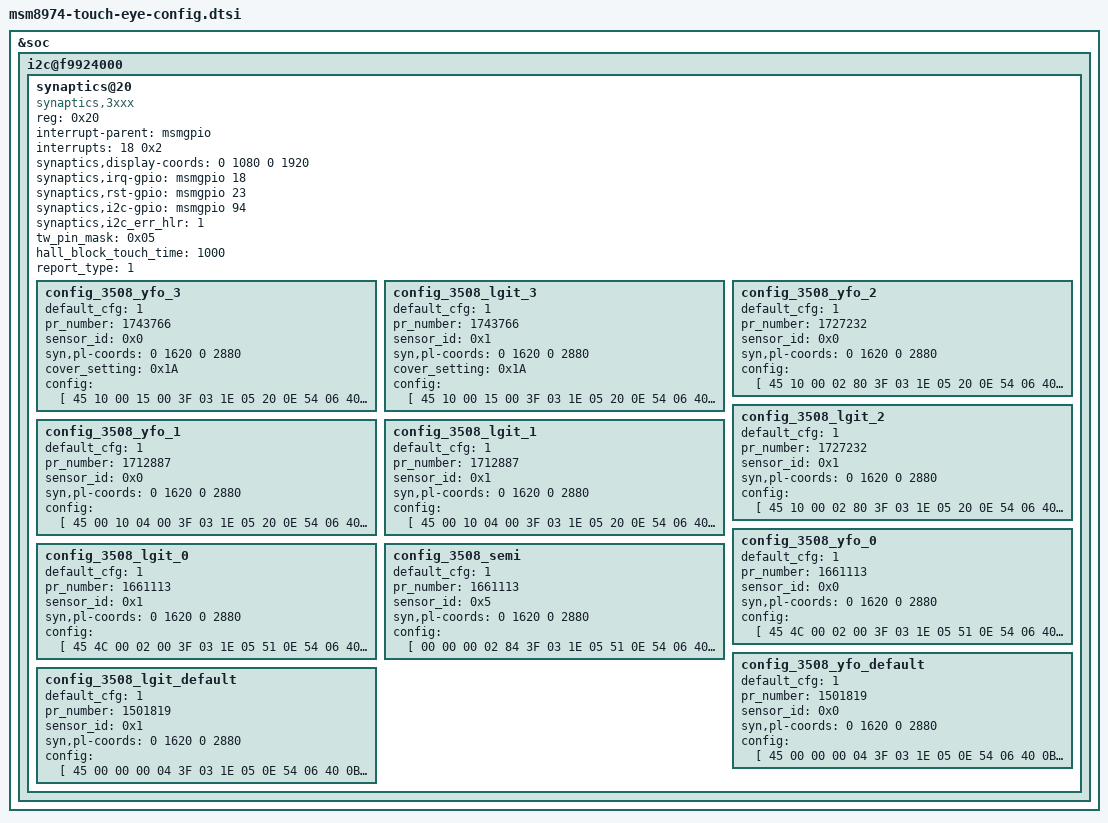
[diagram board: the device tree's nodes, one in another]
/* Copyright (c) 2013, The Linux Foundation. All rights reserved.
 *
 * This program is free software; you can redistribute it and/or modify
 * it under the terms of the GNU General Public License version 2 and
 * only version 2 as published by the Free Software Foundation.
 *
 * This program is distributed in the hope that it will be useful,
 * but WITHOUT ANY WARRANTY; without even the implied warranty of
 * MERCHANTABILITY or FITNESS FOR A PARTICULAR PURPOSE.  See the
 * GNU General Public License for more details.
 */

&soc {
	i2c@f9924000 {
		synaptics@20 {
			compatible               = "synaptics,3xxx";
			reg                      = <0x20>;
			interrupt-parent         = <&msmgpio>;
			interrupts               = <18 0x2>;
			synaptics,display-coords = <0 1080 0 1920>;
			synaptics,irq-gpio       = <&msmgpio 18 0x00>;
			synaptics,rst-gpio       = <&msmgpio 23 0x00>;
			synaptics,i2c-gpio       = <&msmgpio 94 0x00>;
			synaptics,i2c_err_hlr    = <1>;
			tw_pin_mask              = <0x05>;
			hall_block_touch_time    = <1000>;
			report_type              = <1>;

			config_3508_yfo_3 {
				default_cfg   = <1>;
				pr_number     = <1743766>;
				sensor_id     = <0x0>;
				syn,pl-coords = <0 1620 0 2880>;
				cover_setting = <0x1A>;
				config = [
					45 10 00 15 00 3F 03 1E
					05 20 0E 54 06 40 0B 6D
					41 F0 41 00 00 00 00 10
					1C 01 1E 05 EE 0A AC 01
					2D 0B 03 0C 03 55 C5 64
					CA 25 0D 05 8C 00 13 14
					80 0F 0A 78 00 01 01 07
					04 04 1E 40 19 C8 26 26
					80 80 00 00 C8 C0 53 5B
					80 26 19 01 40 40 32 50
					00 00 00 00 4C 04 6C 07
					3C 32 00 00 00 00 4C 04
					6C 07 1E 05 1E 04 0A 04
					0A 00 0A 04 04 01 01 00
					01 05 0A 00 10 00 32 00
					96 00 00 00 14 03 0C 0F
					0A 00 4B 00 FF FF FF FF
					FF FF FF FF FF FF FF FF
					FF FF FF FF FF FF FF FF
					FF FF FF FF FF FF FF FF
					FF FF FF FF FF 00 04 01
					80 0D 1B 00 00 FF F4 01
					FF FF BF 64 C8 00 00 C0
					80 00 10 0A 18 00 79 01
					FA 00 00 58 02 50 00 03
					03 07 07 03 C8 00 01 04
					04 3E 00 18 00 00 00 02
					00 01 29 04 3D 00 17 00
					01 00 02 00 01 2B 84 3B
					00 17 00 02 00 02 00 01
					2C 84 3A 00 17 00 03 00
					02 00 01 2D 04 39 00 16
					00 04 00 05 00 02 26 04
					38 00 16 00 05 00 05 00
					02 27 04 36 00 15 00 08
					00 05 00 02 29 04 35 00
					15 00 09 00 05 00 02 29
					02 03 03 03 03 03 03 03
					03 03 03 03 03 03 03 03
					00 00 00 00 00 00 1D 00
					06 00 A6 00 14 64 00 00
					1B 02 06 FF 14 A0 00 A0
					00 50 32 1E 03 0C 0C 14
					28 04 00 00 00 00 00 00
					00 00 00 00 17 B2 07 01
					03 01 01 01 01 01 03 04
					00 03 01 0B 0B 02 02 03
					04 04 28 00 06 04 00 3E
					2D 00 05 05 00 2A 02 00
					01 00 FA 28 00 2C 01 32
					00 01 FF FF FF FF FF FF
					FF FF FF FF FF FF FF FF
					FF FF FF FF FF FF FF FF
					00 01 00 00 FF FF FF FF
					FF FF FF FF FF FF FF FF
					FF FF FF FF 28 00 2C 01
					19 00 00 00 00 FF FF FF
					FF FF FF FF FF 51 51 51
					51 CD 0D 04 83 10 10 10
					10 61 24 05 11 12 13 14
					15 16 17 18 19 1A 1B 1C
					1D 1E 1F 20 FF FF FF FF
					FF FF 00 01 02 03 04 05
					06 07 08 09 0A 0B 0C 0D
					34 33 32 31 30 2F 2E 2D
					2C 2B 2A 29 28 27 FF FF
					FF FF 00 10 00 10 00 10
					00 10 80 80 80 80 80 80
					80 80 80 80 80 80 80 80
					80 80 80 80 80 80 80 80
					80 80 80 80 80 80 80 80
					80 80 80 80 80 80 80 80
					80 80 80 80 80 80 80 80
					80 80 80 80 80 80 80 80
					00 10 00 10 00 10 00 10
					00 00 23 FF FF FF 0E FF
					FF FF
				];
			};

			config_3508_lgit_3 {
				default_cfg   = <1>;
				pr_number     = <1743766>;
				sensor_id     = <0x1>;
				syn,pl-coords = <0 1620 0 2880>;
				cover_setting = <0x1A>;
				config = [
					45 10 00 15 00 3F 03 1E
					05 20 0E 54 06 40 0B 6D
					41 F0 41 00 00 00 00 10
					1C 01 1E 05 EE 0A AC 01
					2D 0B 03 0C 03 55 C5 64
					CA 25 0D 05 8C 00 13 14
					80 0F 0A 78 00 01 01 07
					04 04 1E 40 19 C8 26 26
					80 80 00 00 C8 C0 53 5B
					80 26 19 01 40 40 32 50
					00 00 00 00 4C 04 6C 07
					3C 32 00 00 00 00 4C 04
					6C 07 1E 05 1E 04 0A 04
					0A 00 0A 04 04 01 01 00
					01 05 0A 00 10 00 32 00
					96 00 00 00 14 03 0C 0F
					0A 00 4B 00 FF FF FF FF
					FF FF FF FF FF FF FF FF
					FF FF FF FF FF FF FF FF
					FF FF FF FF FF FF FF FF
					FF FF FF FF FF 00 04 01
					80 0D 1B 00 00 FF F4 01
					FF FF BF 64 C8 00 00 C0
					80 00 10 0A 18 00 79 01
					FA 00 00 58 02 50 00 03
					03 07 07 03 C8 00 01 04
					04 3E 00 18 00 00 00 02
					00 01 29 04 3D 00 17 00
					01 00 02 00 01 2B 84 3B
					00 17 00 02 00 02 00 01
					2C 84 3A 00 17 00 03 00
					02 00 01 2D 04 39 00 16
					00 04 00 05 00 02 26 04
					38 00 16 00 05 00 05 00
					02 27 04 36 00 15 00 08
					00 05 00 02 29 04 35 00
					15 00 09 00 05 00 02 29
					02 03 03 03 03 03 03 03
					03 03 03 03 03 03 03 03
					00 00 00 00 00 00 1D 00
					06 00 A6 00 14 64 00 00
					1B 02 06 FF 14 A0 00 A0
					00 50 32 1E 03 0C 0C 14
					28 04 00 00 00 00 00 00
					00 00 00 00 17 B2 07 01
					03 01 01 01 01 01 03 04
					00 03 01 0B 0B 02 02 03
					04 04 28 00 06 04 00 3E
					2D 00 05 05 00 2A 02 00
					01 00 FA 28 00 2C 01 32
					00 01 FF FF FF FF FF FF
					FF FF FF FF FF FF FF FF
					FF FF FF FF FF FF FF FF
					00 01 00 00 FF FF FF FF
					FF FF FF FF FF FF FF FF
					FF FF FF FF 28 00 2C 01
					19 00 00 00 00 FF FF FF
					FF FF FF FF FF 51 51 51
					51 CD 0D 04 83 10 10 10
					10 61 24 05 11 12 13 14
					15 16 17 18 19 1A 1B 1C
					1D 1E 1F 20 FF FF FF FF
					FF FF 00 01 02 03 04 05
					06 07 08 09 0A 0B 0C 0D
					34 33 32 31 30 2F 2E 2D
					2C 2B 2A 29 28 27 FF FF
					FF FF 00 10 00 10 00 10
					00 10 80 80 80 80 80 80
					80 80 80 80 80 80 80 80
					80 80 80 80 80 80 80 80
					80 80 80 80 80 80 80 80
					80 80 80 80 80 80 80 80
					80 80 80 80 80 80 80 80
					80 80 80 80 80 80 80 80
					00 10 00 10 00 10 00 10
					00 00 23 FF FF FF 0E FF
					FF FF
				];
			};
			config_3508_yfo_2 {
				default_cfg   = <1>;
				pr_number     = <1727232>;
				sensor_id     = <0x0>;
				syn,pl-coords = <0 1620 0 2880>;
				config = [
					45 10 00 02 80 3F 03 1E
					05 20 0E 54 06 40 0B 6D
					41 F0 41 00 00 00 00 10
					1C 01 1E 05 EE 0A AC 01
					2D 0B 03 0C 03 55 C5 64
					CA 25 0D 05 8C 00 0C 0F
					80 0F 0A 78 00 01 01 07
					04 04 1E 40 19 C8 26 26
					80 80 00 00 C8 C0 53 5B
					80 26 19 01 40 40 32 50
					00 00 00 00 4C 04 6C 07
					3C 32 00 00 00 00 4C 04
					6C 07 1E 05 1E 04 0A 04
					0A 00 0A 04 04 01 01 00
					01 05 0A 00 10 00 32 00
					96 00 00 00 14 03 0C 0F
					0A 00 4B 00 FF FF FF FF
					FF FF FF FF FF FF FF FF
					FF FF FF FF FF FF FF FF
					FF FF FF FF FF FF FF FF
					FF FF FF FF FF 00 04 01
					80 0D 1B 00 00 FF D0 07
					FF FF BF 96 B8 0B 00 C0
					80 00 10 0A 18 00 79 01
					2C 01 00 E8 03 F4 01 03
					03 07 07 03 E8 03 01 04
					84 3E 00 18 00 00 00 02
					00 01 29 04 3D 00 17 00
					01 00 02 00 01 2B 84 3B
					00 17 00 02 00 02 00 01
					2C 04 3A 00 17 00 03 00
					02 00 01 2D 04 39 00 16
					00 04 00 05 00 02 26 04
					38 00 16 00 05 00 05 00
					02 27 84 36 00 15 00 06
					00 05 00 02 28 84 35 00
					15 00 07 00 05 00 02 28
					02 03 03 03 03 03 03 03
					03 03 03 03 03 03 03 03
					00 00 00 00 00 00 1D 00
					06 00 A6 00 14 64 00 00
					1B 02 06 FF 28 A0 00 A0
					00 50 32 1E 03 0C 0C 14
					28 04 00 00 00 00 00 00
					00 00 00 00 17 B2 07 01
					03 01 01 01 01 01 03 04
					00 03 01 0B 0B 02 02 03
					04 04 28 00 06 04 00 3E
					2D 00 05 05 00 2A 02 00
					01 00 FA 28 00 2C 01 32
					00 00 01 00 00 FF FF FF
					FF FF FF FF FF FF FF FF
					FF FF FF FF FF 28 00 2C
					01 19 00 00 00 00 FF FF
					FF FF FF FF FF FF 51 51
					51 51 CD 0D 04 83 10 10
					10 10 61 24 05 11 12 13
					14 15 16 17 18 19 1A 1B
					1C 1D 1E 1F 20 FF FF FF
					FF FF FF 00 01 02 03 04
					05 06 07 08 09 0A 0B 0C
					0D 34 33 32 31 30 2F 2E
					2D 2C 2B 2A 29 28 27 FF
					FF FF FF 00 10 00 10 00
					10 00 10 80 80 80 80 80
					80 80 80 80 80 80 80 80
					80 80 80 80 80 80 80 80
					80 80 80 80 80 80 80 80
					80 80 80 80 80 80 80 80
					80 80 80 80 80 80 80 80
					80 80 80 80 80 80 80 80
					80 00 10 00 10 00 10 00
					10 00 00 23 FF FF FF 0E
					FF FF FF 00 02 02 04
				];
			};

			config_3508_lgit_2 {
				default_cfg   = <1>;
				pr_number     = <1727232>;
				sensor_id     = <0x1>;
				syn,pl-coords = <0 1620 0 2880>;
				config = [
					45 10 00 02 80 3F 03 1E
					05 20 0E 54 06 40 0B 6D
					41 F0 41 00 00 00 00 10
					1C 01 1E 05 EE 0A AC 01
					2D 0B 03 0C 03 55 C5 64
					CA 25 0D 05 8C 00 0C 0F
					80 0F 0A 78 00 01 01 07
					04 04 1E 40 19 C8 26 26
					80 80 00 00 C8 C0 53 5B
					80 26 19 01 40 40 32 50
					00 00 00 00 4C 04 6C 07
					3C 32 00 00 00 00 4C 04
					6C 07 1E 05 1E 04 0A 04
					0A 00 0A 04 04 01 01 00
					01 05 0A 00 10 00 32 00
					96 00 00 00 14 03 0C 0F
					0A 00 4B 00 FF FF FF FF
					FF FF FF FF FF FF FF FF
					FF FF FF FF FF FF FF FF
					FF FF FF FF FF FF FF FF
					FF FF FF FF FF 00 04 01
					80 0D 1B 00 00 FF D0 07
					FF FF BF 96 B8 0B 00 C0
					80 00 10 0A 18 00 79 01
					2C 01 00 E8 03 F4 01 03
					03 07 07 03 E8 03 01 04
					84 3E 00 18 00 00 00 02
					00 01 29 04 3D 00 17 00
					01 00 02 00 01 2B 84 3B
					00 17 00 02 00 02 00 01
					2C 04 3A 00 17 00 03 00
					02 00 01 2D 04 39 00 16
					00 04 00 05 00 02 26 04
					38 00 16 00 05 00 05 00
					02 27 84 36 00 15 00 06
					00 05 00 02 28 84 35 00
					15 00 07 00 05 00 02 28
					02 03 03 03 03 03 03 03
					03 03 03 03 03 03 03 03
					00 00 00 00 00 00 1D 00
					06 00 A6 00 14 64 00 00
					1B 02 06 FF 28 A0 00 A0
					00 50 32 1E 03 0C 0C 14
					28 04 00 00 00 00 00 00
					00 00 00 00 17 B2 07 01
					03 01 01 01 01 01 03 04
					00 03 01 0B 0B 02 02 03
					04 04 28 00 06 04 00 3E
					2D 00 05 05 00 2A 02 00
					01 00 FA 28 00 2C 01 32
					00 00 01 00 00 FF FF FF
					FF FF FF FF FF FF FF FF
					FF FF FF FF FF 28 00 2C
					01 19 00 00 00 00 FF FF
					FF FF FF FF FF FF 51 51
					51 51 CD 0D 04 83 10 10
					10 10 61 24 05 11 12 13
					14 15 16 17 18 19 1A 1B
					1C 1D 1E 1F 20 FF FF FF
					FF FF FF 00 01 02 03 04
					05 06 07 08 09 0A 0B 0C
					0D 34 33 32 31 30 2F 2E
					2D 2C 2B 2A 29 28 27 FF
					FF FF FF 00 10 00 10 00
					10 00 10 80 80 80 80 80
					80 80 80 80 80 80 80 80
					80 80 80 80 80 80 80 80
					80 80 80 80 80 80 80 80
					80 80 80 80 80 80 80 80
					80 80 80 80 80 80 80 80
					80 80 80 80 80 80 80 80
					80 00 10 00 10 00 10 00
					10 00 00 23 FF FF FF 0E
					FF FF FF 00 02 02 04
				];
			};

			config_3508_yfo_1 {
				default_cfg   = <1>;
				pr_number     = <1712887>;
				sensor_id     = <0x0>;
				syn,pl-coords = <0 1620 0 2880>;
				config = [
					45 00 10 04 00 3F 03 1E
					05 20 0E 54 06 40 0B 6D
					41 F0 41 00 00 00 00 10
					1C 01 1E 05 86 04 F9 00
					2D 10 03 0F 03 DE C1 F4
					C7 25 0D 05 8C 00 0C 0F
					80 0F 0A 78 00 01 01 07
					04 04 1E 40 19 C8 26 26
					80 80 00 00 C8 C0 53 5B
					80 1F 1A 01 40 40 32 50
					00 00 00 00 4C 04 6C 07
					3C 32 00 00 00 00 4C 04
					6C 07 1E 05 1E 04 0A 04
					0A 00 0A 04 04 01 01 00
					01 05 0A 00 10 00 32 00
					96 00 00 00 14 03 0C 0F
					0A 00 4B 00 FF FF FF FF
					FF FF FF FF FF FF FF FF
					FF FF FF FF FF FF FF FF
					FF FF FF FF FF FF FF FF
					FF FF FF FF FF 00 04 01
					80 0D 1B 00 00 FF D0 07
					FF FF BF 96 B8 0B 00 C0
					80 00 10 0A 18 00 79 01
					08 00 00 E8 03 F4 01 03
					03 07 07 03 E8 03 01 04
					04 37 00 15 00 00 00 05
					00 02 27 84 36 00 15 00
					01 00 05 00 02 28 84 35
					00 14 00 02 00 05 00 02
					29 04 34 00 14 00 03 00
					05 00 02 29 03 32 00 13
					00 05 00 03 00 01 24 03
					30 00 13 00 07 00 03 00
					01 25 83 2F 00 12 00 09
					00 03 00 01 27 83 2D 00
					11 00 0B 00 03 00 01 28
					03 04 04 04 04 04 03 03
					03 03 03 03 03 03 03 03
					00 00 00 00 00 00 23 00
					06 00 A6 00 14 64 00 00
					1B 02 06 FF 28 A0 00 A0
					00 50 32 1E 03 0C 0C 14
					28 04 00 00 00 00 00 00
					00 00 00 00 14 19 07 03
					03 02 03 03 00 00 03 07
					03 03 02 03 03 00 00 03
					04 04 28 00 06 04 00 37
					2D 00 05 05 00 2A 02 00
					01 00 FA 28 00 2C 01 32
					00 00 FF FF FF FF FF FF
					FF FF FF FF FF FF FF FF
					FF FF FF FF FF FF FF FF
					00 01 00 00 FF FF FF FF
					FF FF FF FF FF FF FF FF
					FF FF FF FF 28 00 2C 01
					19 00 00 00 00 FF FF FF
					FF FF FF FF FF 51 51 51
					51 CD 0D 04 83 10 10 10
					10 61 24 05 11 12 13 14
					15 16 17 18 19 1A 1B 1C
					1D 1E 1F 20 FF FF FF FF
					FF FF 00 01 02 03 04 05
					06 07 08 09 0A 0B 0C 0D
					34 33 32 31 30 2F 2E 2D
					2C 2B 2A 29 28 27 FF FF
					FF FF 00 10 00 10 00 10
					00 10 80 80 80 80 80 80
					80 80 80 80 80 80 80 80
					80 80 80 80 80 80 80 80
					80 80 80 80 80 80 80 80
					80 80 80 80 80 80 80 80
					80 80 80 80 80 80 80 80
					80 80 80 80 80 80 80 80
					00 10 00 10 00 10 00 10
					00 00 23 FF FF FF 0E FF
					FF FF
				];
			};

			config_3508_lgit_1 {
				default_cfg   = <1>;
				pr_number     = <1712887>;
				sensor_id     = <0x1>;
				syn,pl-coords = <0 1620 0 2880>;
				config = [
					45 00 10 04 00 3F 03 1E
					05 20 0E 54 06 40 0B 6D
					41 F0 41 00 00 00 00 10
					1C 01 1E 05 86 04 F9 00
					2D 10 03 0F 03 DE C1 F4
					C7 25 0D 05 8C 00 0C 0F
					80 0F 0A 78 00 01 01 07
					04 04 1E 40 19 C8 26 26
					80 80 00 00 C8 C0 53 5B
					80 1F 1A 01 40 40 32 50
					00 00 00 00 4C 04 6C 07
					3C 32 00 00 00 00 4C 04
					6C 07 1E 05 1E 04 0A 04
					0A 00 0A 04 04 01 01 00
					01 05 0A 00 10 00 32 00
					96 00 00 00 14 03 0C 0F
					0A 00 4B 00 FF FF FF FF
					FF FF FF FF FF FF FF FF
					FF FF FF FF FF FF FF FF
					FF FF FF FF FF FF FF FF
					FF FF FF FF FF 00 04 01
					80 0D 1B 00 00 FF D0 07
					FF FF BF 96 B8 0B 00 C0
					80 00 10 0A 18 00 79 01
					08 00 00 E8 03 F4 01 03
					03 07 07 03 E8 03 01 04
					04 37 00 15 00 00 00 05
					00 02 27 84 36 00 15 00
					01 00 05 00 02 28 84 35
					00 14 00 02 00 05 00 02
					29 04 34 00 14 00 03 00
					05 00 02 29 03 32 00 13
					00 05 00 03 00 01 24 03
					30 00 13 00 07 00 03 00
					01 25 83 2F 00 12 00 09
					00 03 00 01 27 83 2D 00
					11 00 0B 00 03 00 01 28
					03 04 04 04 04 04 03 03
					03 03 03 03 03 03 03 03
					00 00 00 00 00 00 23 00
					06 00 A6 00 14 64 00 00
					1B 02 06 FF 28 A0 00 A0
					00 50 32 1E 03 0C 0C 14
					28 04 00 00 00 00 00 00
					00 00 00 00 14 19 07 03
					03 02 03 03 00 00 03 07
					03 03 02 03 03 00 00 03
					04 04 28 00 06 04 00 37
					2D 00 05 05 00 2A 02 00
					01 00 FA 28 00 2C 01 32
					00 00 FF FF FF FF FF FF
					FF FF FF FF FF FF FF FF
					FF FF FF FF FF FF FF FF
					00 01 00 00 FF FF FF FF
					FF FF FF FF FF FF FF FF
					FF FF FF FF 28 00 2C 01
					19 00 00 00 00 FF FF FF
					FF FF FF FF FF 51 51 51
					51 CD 0D 04 83 10 10 10
					10 61 24 05 11 12 13 14
					15 16 17 18 19 1A 1B 1C
					1D 1E 1F 20 FF FF FF FF
					FF FF 00 01 02 03 04 05
					06 07 08 09 0A 0B 0C 0D
					34 33 32 31 30 2F 2E 2D
					2C 2B 2A 29 28 27 FF FF
					FF FF 00 10 00 10 00 10
					00 10 80 80 80 80 80 80
					80 80 80 80 80 80 80 80
					80 80 80 80 80 80 80 80
					80 80 80 80 80 80 80 80
					80 80 80 80 80 80 80 80
					80 80 80 80 80 80 80 80
					80 80 80 80 80 80 80 80
					00 10 00 10 00 10 00 10
					00 00 23 FF FF FF 0E FF
					FF FF
				];
			};

			config_3508_yfo_0 {
				default_cfg   = <1>;
				pr_number     = <1661113>;
				sensor_id     = <0x0>;
				syn,pl-coords = <0 1620 0 2880>;
				config = [
					45 4C 00 02 00 3F 03 1E
					05 51 0E 54 06 40 0B 00
					40 00 40 00 00 00 00 10
					1C 01 1E 05 F5 28 1E 05
					28 30 00 30 00 F0 D2 F0
					D2 25 0D 05 8C 05 0F 80
					0F 0A 20 00 01 01 07 04
					04 0A C0 19 2A 26 26 80
					80 00 00 50 C0 53 5B 80
					54 19 01 40 40 32 50 00
					00 00 00 4C 04 6C 07 3C
					32 00 00 00 00 4C 04 6C
					07 1E 05 1E 04 0A 04 0A
					00 0A 04 04 00 00 00 00
					05 0A 00 00 00 00 00 14
					03 0C 0F 0A 00 4B 00 FF
					FF FF FF FF FF FF FF FF
					FF FF FF FF FF FF FF FF
					FF FF FF FF FF FF FF FF
					FF FF FF FF FF FF FF FF
					00 F0 00 80 04 1B 00 00
					FF FF FF FF FF FF FF FF
					FF 00 C0 80 00 10 0A 18
					00 79 00 FF FF 01 FF FF
					FF FF 02 02 07 07 05 FF
					FF 01 04 04 3E 00 17 00
					00 00 02 00 01 2C 04 3D
					00 16 00 01 00 05 00 02
					26 04 3B 00 16 00 02 00
					05 00 02 27 04 3A 00 15
					00 03 00 05 00 02 28 04
					39 00 15 00 04 00 05 00
					02 28 04 38 00 14 00 05
					00 05 00 02 29 04 37 00
					14 00 06 00 05 00 02 29
					04 35 00 13 00 08 00 03
					00 01 24 09 09 09 09 09
					09 09 09 09 09 09 09 09
					09 09 09 00 00 00 00 00
					00 20 00 06 00 A6 00 14
					64 00 00 1B 02 00 28 28
					A0 00 A0 00 50 50 1E 03
					0C 0C 14 28 04 00 00 00
					00 00 00 00 00 00 00 16
					19 07 03 03 02 03 03 00
					00 03 07 03 03 02 03 03
					00 00 03 04 04 28 00 05
					04 00 3E 2D 00 05 00 00
					00 00 00 00 00 00 00 FF
					FF FF FF FF FF FF FF 51
					51 51 51 CD 0D 04 83 10
					10 10 10 05 11 12 13 14
					15 16 17 18 19 1A 1B 1C
					1D 1E 1F 20 FF FF FF FF
					FF FF 00 01 02 03 04 05
					06 07 08 09 0A 0B 0C 0D
					34 33 32 31 30 2F 2E 2D
					2C 2B 2A 29 28 27 FF FF
					FF FF 00 10 00 10 00 10
					00 10 80 80 80 80 80 80
					80 80 80 80 80 80 80 80
					80 80 80 80 80 80 80 80
					80 80 80 80 80 80 80 80
					80 80 80 80 80 80 80 80
					80 80 80 80 80 80 80 80
					80 80 80 80 80 80 80 80
					00 10 00 10 00 10 00 10
					00 00 23 FF FF FF 0E FF
					FF FF 00 02 0A 32
				];
			};

			config_3508_lgit_0 {
				default_cfg   = <1>;
				pr_number     = <1661113>;
				sensor_id     = <0x1>;
				syn,pl-coords = <0 1620 0 2880>;
				config = [
					45 4C 00 02 00 3F 03 1E
					05 51 0E 54 06 40 0B 00
					40 00 40 00 00 00 00 10
					1C 01 1E 05 F5 28 1E 05
					28 30 00 30 00 F0 D2 F0
					D2 25 0D 05 8C 05 0F 80
					0F 0A 20 00 01 01 07 04
					04 0A C0 19 2A 26 26 80
					80 00 00 50 C0 53 5B 80
					54 19 01 40 40 32 50 00
					00 00 00 4C 04 6C 07 3C
					32 00 00 00 00 4C 04 6C
					07 1E 05 1E 04 0A 04 0A
					00 0A 04 04 00 00 00 00
					05 0A 00 00 00 00 00 14
					03 0C 0F 0A 00 4B 00 FF
					FF FF FF FF FF FF FF FF
					FF FF FF FF FF FF FF FF
					FF FF FF FF FF FF FF FF
					FF FF FF FF FF FF FF FF
					00 F0 00 80 04 1B 00 00
					FF FF FF FF FF FF FF FF
					FF 00 C0 80 00 10 0A 18
					00 79 00 FF FF 01 FF FF
					FF FF 02 02 07 07 05 FF
					FF 01 04 04 3E 00 17 00
					00 00 02 00 01 2C 04 3D
					00 16 00 01 00 05 00 02
					26 04 3B 00 16 00 02 00
					05 00 02 27 04 3A 00 15
					00 03 00 05 00 02 28 04
					39 00 15 00 04 00 05 00
					02 28 04 38 00 14 00 05
					00 05 00 02 29 04 37 00
					14 00 06 00 05 00 02 29
					04 35 00 13 00 08 00 03
					00 01 24 09 09 09 09 09
					09 09 09 09 09 09 09 09
					09 09 09 00 00 00 00 00
					00 20 00 06 00 A6 00 14
					64 00 00 1B 02 00 28 28
					A0 00 A0 00 50 50 1E 03
					0C 0C 14 28 04 00 00 00
					00 00 00 00 00 00 00 16
					19 07 03 03 02 03 03 00
					00 03 07 03 03 02 03 03
					00 00 03 04 04 28 00 05
					04 00 3E 2D 00 05 00 00
					00 00 00 00 00 00 00 FF
					FF FF FF FF FF FF FF 51
					51 51 51 CD 0D 04 83 10
					10 10 10 05 11 12 13 14
					15 16 17 18 19 1A 1B 1C
					1D 1E 1F 20 FF FF FF FF
					FF FF 00 01 02 03 04 05
					06 07 08 09 0A 0B 0C 0D
					34 33 32 31 30 2F 2E 2D
					2C 2B 2A 29 28 27 FF FF
					FF FF 00 10 00 10 00 10
					00 10 80 80 80 80 80 80
					80 80 80 80 80 80 80 80
					80 80 80 80 80 80 80 80
					80 80 80 80 80 80 80 80
					80 80 80 80 80 80 80 80
					80 80 80 80 80 80 80 80
					80 80 80 80 80 80 80 80
					00 10 00 10 00 10 00 10
					00 00 23 FF FF FF 0E FF
					FF FF 00 02 0A 32
				];
			};

			config_3508_semi {
				default_cfg   = <1>;
				pr_number     = <1661113>;
				sensor_id     = <0x5>;
				syn,pl-coords = <0 1620 0 2880>;
				config = [
					00 00 00 02 84 3F 03 1E
					05 51 0E 54 06 40 0B 00
					40 00 40 00 00 00 00 0F
					1B 01 1E 05 F5 28 1E 05
					28 30 00 30 00 F0 D2 F0
					D2 25 0D 05 8C 05 0F 80
					0F 0A 20 00 01 01 07 04
					04 0A C0 19 2A 26 26 80
					80 00 00 50 C0 53 5B 80
					1E 19 01 40 40 32 50 00
					00 00 00 4C 04 6C 07 3C
					32 00 00 00 00 4C 04 6C
					07 1E 05 1E 04 0A 04 0A
					00 0A 04 04 00 00 00 00
					05 0A 00 00 00 00 00 14
					03 0C 0F 0A 00 4B 00 FF
					FF FF FF FF FF FF FF FF
					FF FF FF FF FF FF FF FF
					FF FF FF FF FF FF FF FF
					FF FF FF FF FF FF FF FF
					00 CF 00 80 04 1B 00 00
					FF FF FF FF FF FF FF FF
					FF 00 C0 80 00 10 0A 18
					00 79 00 FF FF 01 FF FF
					FF FF 06 06 07 07 00 FF
					FF 01 04 03 31 00 11 00
					00 00 03 00 01 28 03 30
					00 11 00 02 00 07 00 02
					24 03 2E 00 10 00 04 00
					07 00 02 25 03 2D 00 10
					00 06 00 07 00 02 26 03
					2C 00 0F 00 08 00 07 00
					02 27 03 2A 00 0F 00 0A
					00 04 00 01 24 03 29 00
					0E 00 0C 00 04 00 01 24
					03 28 00 0E 00 0E 00 04
					00 01 25 05 06 06 06 04
					06 06 06 06 06 06 06 06
					07 06 00 00 00 00 00 00
					00 2F 00 06 00 A6 00 14
					64 00 00 1B 02 00 28 28
					A0 00 A0 00 50 50 1E 03
					0C 0C 14 28 04 00 00 00
					00 00 00 00 00 00 00 13
					19 07 03 03 02 03 03 00
					00 03 07 03 03 02 03 03
					00 00 03 04 04 28 00 05
					03 00 31 22 00 05 00 00
					00 00 00 00 00 00 00 FF
					FF FF FF FF FF FF FF 51
					51 51 51 CD 0D 04 83 10
					10 10 10 05 20 1F 1E 1D
					1C 1B 1A 18 17 16 15 14
					13 12 11 FF FF FF FF FF
					FF FF 00 01 02 03 04 05
					06 07 08 09 0A 0B 0C 0D
					33 32 31 30 2F 2E 2D 2C
					2B 2A 29 28 27 FF FF FF
					FF FF 00 10 00 10 00 10
					00 10 80 80 80 80 80 80
					80 80 80 80 80 80 80 80
					80 80 80 80 80 80 80 80
					80 80 80 80 80 80 80 80
					80 80 80 80 80 80 80 80
					80 80 80 80 80 80 80 80
					80 80 80 80 80 80 80 80
					00 10 00 10 00 10 00 10
					00 00 21 22 FF FF 0E 26
					FF FF 00 02 0A 32
				];
			};

			config_3508_yfo_default {
				default_cfg   = <1>;
				pr_number     = <1501819>;
				sensor_id     = <0x0>;
				syn,pl-coords = <0 1620 0 2880>;
				config = [
					45 00 00 00 04 3F 03 1E
					05 0E 54 06 40 0B 6D 41
					F0 41 00 00 00 00 10 1C
					01 1E 05 BF 0C CA 02 2D
					18 02 19 02 B0 C1 64 C6
					89 80 C4 C4 05 03 05 0F
					80 0F 0A 20 00 01 01 07
					04 04 0A C0 19 64 26 26
					80 80 00 00 3C 19 01 40
					40 32 50 80 32 00 00 00
					00 4C 04 6C 07 3C 32 00
					00 00 00 4C 04 6C 07 1E
					05 00 00 00 00 05 0A 00
					03 FF 00 04 01 80 04 1B
					00 00 00 FF FF FF FF FF
					FF FF FF 00 C0 80 00 10
					0A 18 00 71 00 FF FF 00
					FF FF FF FF 03 03 07 07
					03 FF FF 01 04 86 4B 00
					11 00 00 00 05 00 02 26
					06 4A 00 11 00 01 00 05
					00 02 28 86 48 00 11 00
					02 00 05 00 02 28 85 47
					00 10 00 03 00 05 00 02
					29 05 46 00 10 00 04 00
					05 00 02 29 05 43 00 10
					00 06 00 03 00 01 24 05
					41 00 0F 00 08 00 03 00
					01 25 85 3E 00 0F 00 0A
					00 03 00 01 27 09 09 09
					09 09 09 09 09 09 09 09
					09 09 09 09 09 00 00 00
					00 00 00 23 00 05 00 A6
					00 14 64 05 00 1B 00 11
					0A 32 0A 32 14 20 46 00
					00 00 FF FF FF FF FF FF
					FF FF 51 51 51 51 CD 0D
					04 83 10 10 10 10 05 11
					12 13 14 15 16 17 18 19
					1A 1B 1C 1D 1E 1F 20 FF
					FF FF FF FF FF 00 01 02
					03 04 05 06 07 08 09 0A
					0B 0C 0D 34 33 32 31 30
					2F 2E 2D 2C 2B 2A 29 28
					27 FF FF FF FF 00 10 00
					10 00 10 00 10 80 80 80
					80 80 80 80 80 80 80 80
					80 80 80 80 80 80 80 80
					80 80 80 80 80 80 80 80
					80 80 80 80 80 80 80 80
					80 80 80 80 80 80 80 80
					80 80 80 80 80 80 80 80
					80 80 80 00 10 00 10 00
					10 00 10
				];
			};

			config_3508_lgit_default {
				default_cfg   = <1>;
				pr_number     = <1501819>;
				sensor_id     = <0x1>;
				syn,pl-coords = <0 1620 0 2880>;
				config = [
					45 00 00 00 04 3F 03 1E
					05 0E 54 06 40 0B 6D 41
					F0 41 00 00 00 00 10 1C
					01 1E 05 BF 0C CA 02 2D
					18 02 19 02 B0 C1 64 C6
					89 80 C4 C4 05 03 05 0F
					80 0F 0A 20 00 01 01 07
					04 04 0A C0 19 64 26 26
					80 80 00 00 3C 19 01 40
					40 32 50 80 32 00 00 00
					00 4C 04 6C 07 3C 32 00
					00 00 00 4C 04 6C 07 1E
					05 00 00 00 00 05 0A 00
					03 FF 00 04 01 80 04 1B
					00 00 00 FF FF FF FF FF
					FF FF FF 00 C0 80 00 10
					0A 18 00 71 00 FF FF 00
					FF FF FF FF 03 03 07 07
					03 FF FF 01 04 86 4B 00
					11 00 00 00 05 00 02 26
					06 4A 00 11 00 01 00 05
					00 02 28 86 48 00 11 00
					02 00 05 00 02 28 85 47
					00 10 00 03 00 05 00 02
					29 05 46 00 10 00 04 00
					05 00 02 29 05 43 00 10
					00 06 00 03 00 01 24 05
					41 00 0F 00 08 00 03 00
					01 25 85 3E 00 0F 00 0A
					00 03 00 01 27 09 09 09
					09 09 09 09 09 09 09 09
					09 09 09 09 09 00 00 00
					00 00 00 23 00 05 00 A6
					00 14 64 05 00 1B 00 11
					0A 32 0A 32 14 20 46 00
					00 00 FF FF FF FF FF FF
					FF FF 51 51 51 51 CD 0D
					04 83 10 10 10 10 05 11
					12 13 14 15 16 17 18 19
					1A 1B 1C 1D 1E 1F 20 FF
					FF FF FF FF FF 00 01 02
					03 04 05 06 07 08 09 0A
					0B 0C 0D 34 33 32 31 30
					2F 2E 2D 2C 2B 2A 29 28
					27 FF FF FF FF 00 10 00
					10 00 10 00 10 80 80 80
					80 80 80 80 80 80 80 80
					80 80 80 80 80 80 80 80
					80 80 80 80 80 80 80 80
					80 80 80 80 80 80 80 80
					80 80 80 80 80 80 80 80
					80 80 80 80 80 80 80 80
					80 80 80 00 10 00 10 00
					10 00 10
				];
			};
		};
	};
};

